# STM32F217 register map
File version: 1.1
CPU: CM3 r1p1, little endian, no MPU, no FPU, 4 interrupt priority bits
Registers are 32-bit, read-write, reset 0x0 unless marked. A register's access mark holds for its fields unless they carry their own. Offsets are from the block's base; [hi:lo] are bit positions.

## Ethernet_PTP — Ethernet: Precision time protocol
Base 0x40028700
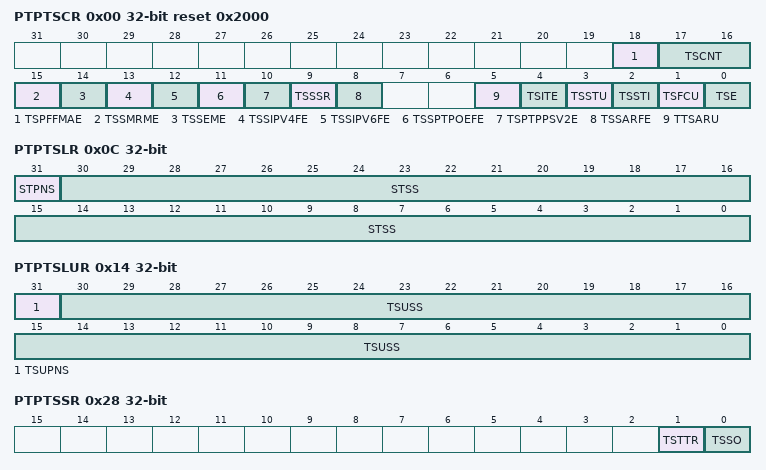
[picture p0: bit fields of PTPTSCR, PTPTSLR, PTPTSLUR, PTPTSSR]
0x00 PTPTSCR reset 0x2000 — Ethernet PTP time stamp control register
  [18] TSPFFMAE — Time stamp PTP frame filtering MAC address enable
  [17:16] TSCNT — Time stamp clock node type
  [15] TSSMRME — Time stamp snapshot for message relevant to master enable
  [14] TSSEME — Time stamp snapshot for event message enable
  [13] TSSIPV4FE — Time stamp snapshot for IPv4 frames enable
  [12] TSSIPV6FE — Time stamp snapshot for IPv6 frames enable
  [11] TSSPTPOEFE — Time stamp snapshot for PTP over ethernet frames enable
  [10] TSPTPPSV2E — Time stamp PTP packet snooping for version2 format enable
  [9] TSSSR — Time stamp subsecond rollover: digital or binary rollover control
  [8] TSSARFE — Time stamp snapshot for all received frames enable
  [5] TTSARU — Time stamp addend register update
  [4] TSITE — Time stamp interrupt trigger enable
  [3] TSSTU — Time stamp system time update
  [2] TSSTI — Time stamp system time initialize
  [1] TSFCU — Time stamp fine or coarse update
  [0] TSE — Time stamp enable
0x04 PTPSSIR — Ethernet PTP subsecond increment register
  [7:0] STSSI — System time subsecond increment
0x08 PTPTSHR ro — Ethernet PTP time stamp high register
  [31:0] STS — System time second
0x0C PTPTSLR ro — Ethernet PTP time stamp low register
  [31] STPNS — System time positive or negative sign
  [30:0] STSS — System time subseconds
0x10 PTPTSHUR — Ethernet PTP time stamp high update register
  [31:0] TSUS — Time stamp update second
0x14 PTPTSLUR — Ethernet PTP time stamp low update register
  [31] TSUPNS — Time stamp update positive or negative sign
  [30:0] TSUSS — Time stamp update subseconds
0x18 PTPTSAR — Ethernet PTP time stamp addend register
  [31:0] TSA — Time stamp addend
0x1C PTPTTHR — Ethernet PTP target time high register
  [31:0] TTSH — Target time stamp high
0x20 PTPTTLR — Ethernet PTP target time low register
  [31:0] TTSL — Target time stamp low
0x28 PTPTSSR ro — Ethernet PTP time stamp status register
  [1] TSTTR — Time stamp target time reached
  [0] TSSO — Time stamp second overflow
0x2C PTPPPSCR ro — Ethernet PTP PPS control register
  [3:0] PPSFREQ — PPS frequency selection
    0=Hz_1 (1 Hz with a pulse width of 125 ms for binary rollover and of 100 ms for digital rollover); 1=Hz_2 (2 Hz with 50% duty cycle for binary rollover (digital rollover not recommended)); 2=Hz_4 (4 Hz with 50% duty cycle for binary rollover (digital rollover not recommended)); 3=Hz_8 (8 Hz with 50% duty cycle for binary rollover (digital rollover not recommended)); 4=Hz_16 (16 Hz with 50% duty cycle for binary rollover (digital rollover not recommended)); 5=Hz_32 (32 Hz with 50% duty cycle for binary rollover (digital rollover not recommended)); 6=Hz_64 (64 Hz with 50% duty cycle for binary rollover (digital rollover not recommended)); 7=Hz_128 (128 Hz with 50% duty cycle for binary rollover (digital rollover not recommended)); 8=Hz_256 (256 Hz with 50% duty cycle for binary rollover (digital rollover not recommended)); 9=Hz_512 (512 Hz with 50% duty cycle for binary rollover (digital rollover not recommended)); 10=Hz_1024 (1024 Hz with 50% duty cycle for binary rollover (digital rollover not recommended)); 11=Hz_2048 (2048 Hz with 50% duty cycle for binary rollover (digital rollover not recommended)); 12=Hz_4096 (4096 Hz with 50% duty cycle for binary rollover (digital rollover not recommended)); 13=Hz_8192 (8192 Hz with 50% duty cycle for binary rollover (digital rollover not recommended)); 14=Hz_16384 (16384 Hz with 50% duty cycle for binary rollover (digital rollover not recommended)); 15=Hz_32768 (32768 Hz with 50% duty cycle for binary rollover (digital rollover not recommended))
